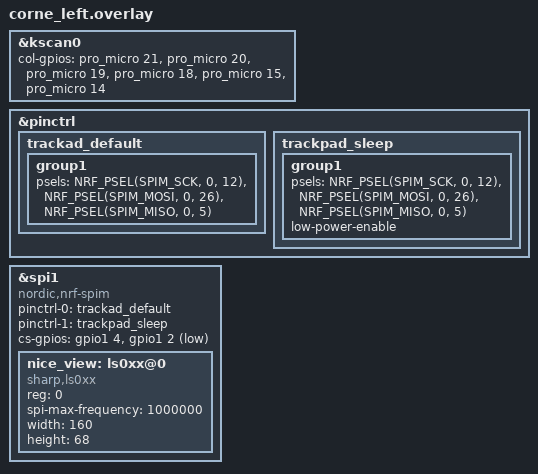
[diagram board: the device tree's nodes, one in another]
/*
 * Copyright (c) 2020 Pete Johanson
 *
 * SPDX-License-Identifier: MIT
 */

#include "corne.dtsi"

&kscan0 {
    col-gpios
        = <&pro_micro 21 GPIO_ACTIVE_HIGH>
        , <&pro_micro 20 GPIO_ACTIVE_HIGH>
        , <&pro_micro 19 GPIO_ACTIVE_HIGH>
        , <&pro_micro 18 GPIO_ACTIVE_HIGH>
        , <&pro_micro 15 GPIO_ACTIVE_HIGH>
        , <&pro_micro 14 GPIO_ACTIVE_HIGH>
        ;
};


&pinctrl {
    trackad_default: trackad_default {
        group1 {
            psels = <NRF_PSEL(SPIM_SCK,  0, 12)>,
                    <NRF_PSEL(SPIM_MOSI, 0, 26)>,
                    <NRF_PSEL(SPIM_MISO, 0, 5)>; 
        };
    };
    trackpad_sleep: trackpad_sleep {
        group1 {
            psels = <NRF_PSEL(SPIM_SCK,  0, 12)>,  
                    <NRF_PSEL(SPIM_MOSI, 0, 26)>,
                    <NRF_PSEL(SPIM_MISO, 0, 5)>; 
            low-power-enable;
        };
    };
};

// nice_view_spi: &spi1 {
//     status = "okay";
//     compatible = "nordic,nrf-spim";
//     pinctrl-0 = <&trackad_default>;
//     pinctrl-1 = <&trackpad_sleep>;
//     pinctrl-names = "default", "sleep";
//     cs-gpios = <&gpio1 4 GPIO_ACTIVE_HIGH>;
// };

&spi1 {
    status = "okay";
    compatible = "nordic,nrf-spim";
    pinctrl-0 = <&trackad_default>; // Ensure this pinctrl is defined in the left overlay
    pinctrl-1 = <&trackpad_sleep>;
    pinctrl-names = "default", "sleep";
    cs-gpios = <&gpio1 4 GPIO_ACTIVE_HIGH>, <&gpio1 2 GPIO_ACTIVE_LOW>;

    nice_view: ls0xx@0 {
        compatible = "sharp,ls0xx";
        reg = <0>;
        spi-max-frequency = <1000000>;
        width = <160>;
        height = <68>;
    };
};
